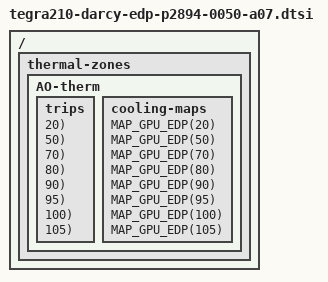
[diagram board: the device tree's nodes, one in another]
/*
 * Copyright (c) 2014-2016, NVIDIA CORPORATION.  All rights reserved.
 *
 * This program is free software; you can redistribute it and/or modify
 * it under the terms of the GNU General Public License as published by
 * the Free Software Foundation; version 2 of the License.
 *
 * This program is distributed in the hope that it will be useful, but WITHOUT
 * ANY WARRANTY; without even the implied warranty of MERCHANTABILITY or
 * FITNESS FOR A PARTICULAR PURPOSE.  See the GNU General Public License for
 * more details.
 *
 * You should have received a copy of the GNU General Public License along
 * with this program; if not, write to the Free Software Foundation, Inc.,
 * 51 Franklin Street, Fifth Floor, Boston, MA  02110-1301, USA.
 *
 */

/ {
	thermal-zones {
		/delete-node/ Tdiode_tegra;

		AO-therm {
			trips {
				MAKE_EDP_TRIP(gpu, 20);
				MAKE_EDP_TRIP(gpu, 50);
				MAKE_EDP_TRIP(gpu, 70);
				MAKE_EDP_TRIP(gpu, 80);
				MAKE_EDP_TRIP(gpu, 90);
				MAKE_EDP_TRIP(gpu, 95);
				MAKE_EDP_TRIP(gpu, 100);
				MAKE_EDP_TRIP(gpu, 105);
			};
			cooling-maps {
				MAP_GPU_EDP(20);
				MAP_GPU_EDP(50);
				MAP_GPU_EDP(70);
				MAP_GPU_EDP(80);
				MAP_GPU_EDP(90);
				MAP_GPU_EDP(95);
				MAP_GPU_EDP(100);
				MAP_GPU_EDP(105);
			};
		};
	};
};
